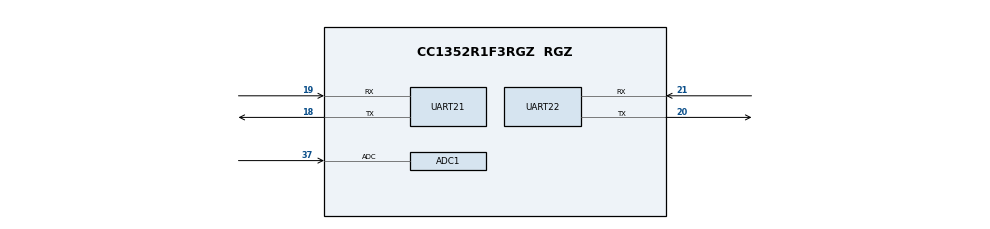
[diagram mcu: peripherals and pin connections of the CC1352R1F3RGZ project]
/**
 * @cliArgs --device "CC1352R1F3RGZ" --package "RGZ" --part "Default" --product "simplelink_cc13x2_26x2_sdk@5.10.00.48"
 * @versions {"data":"2021040816","timestamp":"2021040816","tool":"1.8.1+1900","templates":null}
 */

/**
 * Import the modules used in this configuration.
 */
const CCFG     = scripting.addModule("/ti/devices/CCFG");
const ADC      = scripting.addModule("/ti/drivers/ADC", {}, false);
const ADC1     = ADC.addInstance();
const DMA      = scripting.addModule("/ti/drivers/DMA");
const RTOS     = scripting.addModule("/ti/drivers/RTOS");
const UART2    = scripting.addModule("/ti/drivers/UART2", {}, false);
const UART21   = UART2.addInstance();
const UART22   = UART2.addInstance();
const easylink = scripting.addModule("/ti/easylink/easylink");

/**
 * Write custom configuration values to the imported modules.
 */
CCFG.forceVddr          = true;
CCFG.ccfgTemplate.$name = "ti_devices_CCFGTemplate0";

ADC1.$name                = "ADC_DIO24";
ADC1.samplingDuration     = "10.6 us";
ADC1.adc.$assign          = "ADC0";
ADC1.adc.adcPin.$assign   = "37";
ADC1.adcPinInstance.$name = "CONFIG_PIN_0";

UART21.$name               = "UART0";
UART21.uart.$assign        = "UART0";
UART21.uart.txPin.$assign  = "18";
UART21.uart.rxPin.$assign  = "19";
UART21.txPinInstance.$name = "CONFIG_PIN_2";
UART21.rxPinInstance.$name = "CONFIG_PIN_3";

UART22.$name                    = "UART1";
UART22.rxRingBufferSize         = 256;
UART22.rxInterruptFifoThreshold = "1/8";
UART22.uart.$assign             = "UART1";
UART22.uart.txPin.$assign       = "20";
UART22.uart.rxPin.$assign       = "21";
UART22.txPinInstance.$name      = "CONFIG_PIN_1";
UART22.rxPinInstance.$name      = "CONFIG_PIN_4";

easylink.EasyLink_Phy_5kbpsSlLr                                    = true;
easylink.EasyLink_Phy_50kbps2gfsk                                  = true;
easylink.EasyLink_Phy_200kbps2gfsk                                 = true;
easylink.EasyLink_Phy_Custom                                       = false;
easylink.addrFilters                                               = "";
easylink.enableAddrFilter                                          = false;
easylink.defaultPhy                                                = "EasyLink_Phy_5kbpsSlLr";
easylink.radioConfigEasylinkPhy5kbpssllr.carrierFrequency          = 915.0000;
easylink.radioConfigEasylinkPhy5kbpssllr.codeExportConfig.$name    = "ti_devices_radioconfig_code_export_param1";
easylink.radioConfigEasylinkPhy50kbps2gfsk.carrierFrequency        = 915.0000;
easylink.radioConfigEasylinkPhy50kbps2gfsk.codeExportConfig.$name  = "ti_devices_radioconfig_code_export_param0";
easylink.radioConfigEasylinkPhy200kbps2gfsk.carrierFrequency       = 915.0000;
easylink.radioConfigEasylinkPhy200kbps2gfsk.codeExportConfig.$name = "ti_devices_radioconfig_code_export_param2";
